# AT91SAM9M10 register map
Vendor: Atmel; File version: 20130207
CPU: 
Registers are 32-bit, read-write, no defined reset value unless marked. A register's access mark holds for its fields unless they carry their own. Offsets are from the block's base; [hi:lo] are bit positions; {n}, {i} and the like mark numbered series.

## VDEC — Video Decoder
Base 0x00900000; register names take the prefix VDEC_
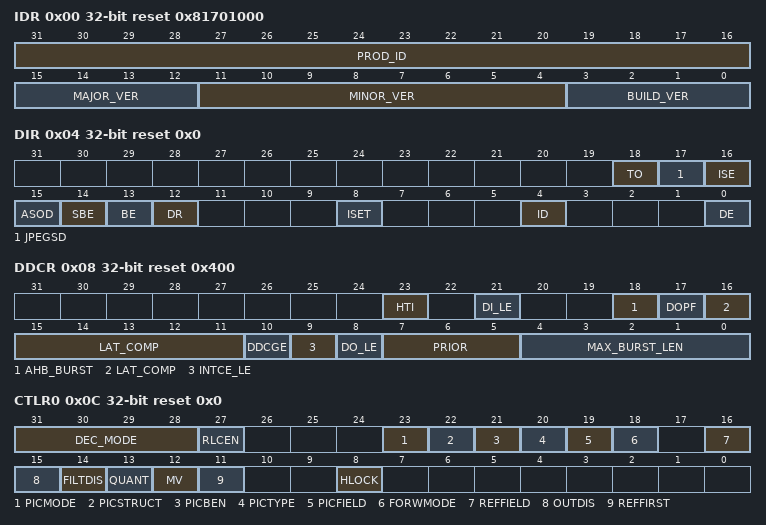
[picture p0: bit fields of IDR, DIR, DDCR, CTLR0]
0x00 IDR ro reset 0x81701000 — ID Register
  [31:16] PROD_ID — Product ID
  [15:12] MAJOR_VER — Major Version
  [11:4] MINOR_VER — Minor Version
  [3:0] BUILD_VER — Build Version
0x04 DIR reset 0x0 — Decoder Interrupt Register
  [18] TO — Timeout
  [17] JPEGSD — JPEG Slice Decoded
  [16] ISE — Input Stream Error
  [15] ASOD — ASO Detected
  [14] SBE — Stream Buffer Empty
  [13] BE — Bus Error
  [12] DR — Decoder Ready
  [8] ISET — Decoder Interrupt Set
  [4] ID — Interrupt Disable
  [0] DE — Decoder Enable
0x08 DDCR reset 0x400 — Decoder Device Configuration Register
  [23] HTI — Hardware Timeout Interrupt Enable
  [21] DI_LE — Decoder Input Endian Mode
  [18] AHB_BURST — AHB Precise Burst and Data Discard Enable
  [17] DOPF — Decoder Output Picture Format
  [16:11] LAT_COMP — Decoder Latency Compensation
  [10] DDCGE — Decoder Dynamic Clock Gating Enable
  [9] INTCE_LE — Interface Endian Mode
  [8] DO_LE — Decoder Output Endian Mode
  [7:5] PRIOR — Decoder Core Internal Bus Service Priority
  [4:0] MAX_BURST_LEN — Maximum Burst Length for Decoder Bus Transactions
0x0C CTLR0 reset 0x0 — Decoder Control Register 0
  [31:28] DEC_MODE — Decoding Mode
  [27] RLCEN — RLC Mode Enable
  [23] PICMODE — Coding mode of Current Picture
  [22] PICSTRUCT — Structure of the Current Picture
  [21] PICBEN — B Picture Enable
  [20] PICTYPE — Picture Type
  [19] PICFIELD — Picture Field
  [18] FORWMODE — Coding Mode of Forward Reference Picture
  [16] REFFIELD — Indicates Which Field Should Be Used As Reference
  [15] OUTDIS — Disable Decoder Output Picture Writing
  [14] FILTDIS — De-block Filtering Disable
  [13] QUANT — Quantization
  [12] MV — MPEG-2 Motion Vector Write Enable
  [11] REFFIRST — Reference Field First
  [8] HLOCK — HLOCK Enable
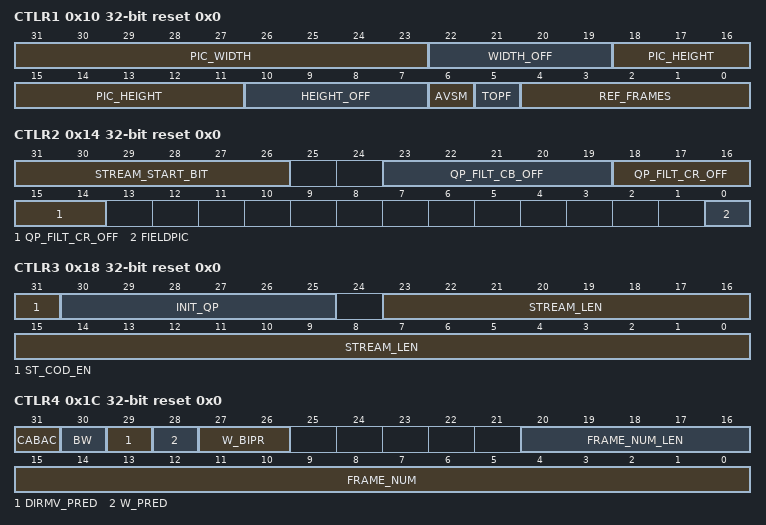
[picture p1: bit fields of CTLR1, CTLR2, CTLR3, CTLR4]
0x10 CTLR1 reset 0x0 — Decoder Control Register 1
  [31:23] PIC_WIDTH — Picture Width
  [22:19] WIDTH_OFF — Width Offset
  [18:11] PIC_HEIGHT — Picture Height
  [10:7] HEIGHT_OFF — Height Offset
  [6] AVSM — Alternative Vertical Scan Method
  [5] TOPF — Top Field
  [4:0] REF_FRAMES — Number of Reference Frames/Semantics
0x14 CTLR2 reset 0x0 — Decoder Control Register 2
  [31:26] STREAM_START_BIT
  [23:19] QP_FILT_CB_OFF
  [18:14] QP_FILT_CR_OFF
  [0] FIELDPIC — Flag for Stream
0x18 CTLR3 reset 0x0 — Decoder Control Register 3
  [31] ST_COD_EN — Stream Start Code
  [30:25] INIT_QP — Quantization Initialization
  [23:0] STREAM_LEN — Stream Length
0x1C CTLR4 reset 0x0 — Decoder Control Register 4
  [31] CABAC — H.264 CABAC Enable
  [30] BW — Black and White Enable
  [29] DIRMV_PRED — Derive Luma Method
  [28] W_PRED — Weight Prediction
  [27:26] W_BIPR — Weight Prediction for B Slices
  [20:16] FRAME_NUM_LEN — Frame Number length
  [15:0] FRAME_NUM — Frame Number
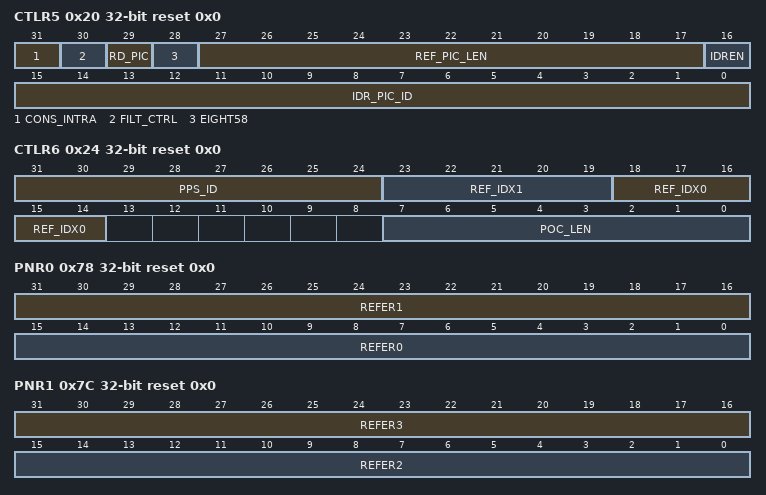
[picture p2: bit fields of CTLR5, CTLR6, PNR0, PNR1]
0x20 CTLR5 reset 0x0 — Decoder Control Register 5
  [31] CONS_INTRA — Intra in Prediction
  [30] FILT_CTRL — Extra Variables Controlling Characteristics of The Deblocking Filter
  [29] RD_PIC — Redundant Picture Present
  [28] EIGHT58
  [27:17] REF_PIC_LEN — Reference Picture Length
  [16] IDREN — IDR Picture Enable
  [15:0] IDR_PIC_ID — IDR Picture
0x24 CTLR6 reset 0x0 — Decoder Control Register 6
  [31:24] PPS_ID — Picture Parameter
  [23:19] REF_IDX1 — Maximum Reference Index 1
  [18:14] REF_IDX0 — Maximum Reference Index 0
  [7:0] POC_LEN — Picture Order length
0x28 DMVBA reset 0x0 — Base Address for Differential Motion Vector
  [31:2] MV_CONTROL_BASE — Differential Motion Vector Base Address
0x2C CTLR7 reset 0x0 — Decoder Control Register 7
  [31:2] BA — Base Address
0x30 RLCVLCBA reset 0x0 — RLC/VLC Data Base Address
  [31:2] BA — Base Address
0x34 PICTBA reset 0x0 — Decoded Picture Base Address
  [31:2] BA — Base Address
{0x38+4i} PIDXBA[{i}] (i=0..15) — Reference Picture Index 0 Base Address
  [31:2] BA — Base Address
0x78 PNR0 reset 0x0 — Reference Picture Numbers Register 0
  [31:16] REFER1 — Reference Picture Number for Index 1
  [15:0] REFER0 — Reference Picture Number for Index 0
0x7C PNR1 reset 0x0 — Reference Picture Numbers Register 1
  [31:16] REFER3 — Reference Picture Number for Index 3
  [15:0] REFER2 — Reference Picture Number for Index 2
0x80 PNR2 reset 0x0 — Reference Picture Numbers Register 2
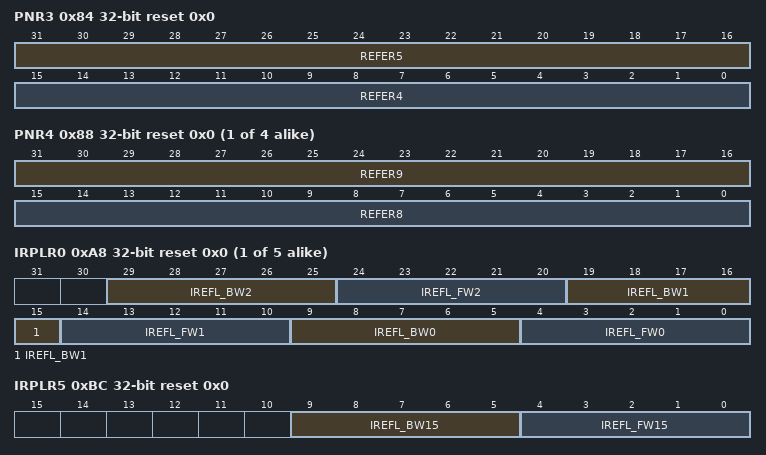
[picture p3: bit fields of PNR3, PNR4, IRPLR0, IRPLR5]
0x84 PNR3 reset 0x0 — Reference Picture Numbers Register 3
  [31:16] REFER5 — Reference Picture Number for Index 5
  [15:0] REFER4 — Reference Picture Number for Index 4
{0x78+4i} PNR{i} reset 0x0 (i=4..7) — Reference Picture Numbers Register {i}
  [31:16] REFER{2i+1} — Reference Picture Number for Index {2i+1}
  [15:0] REFER{2i} — Reference Picture Number for Index {2i}
0x98 PLTFR reset 0x0 — Reference Picture Long Term Flag Register
  [31:0] LTF — Long Term Flag
0x9C PVFR reset 0x0 — Reference Picture Valid Flag Register
0xA0 SDTBA reset 0x0 — Standard Dependent Tables Base Address
  [31:2] BA — Base Address
0xA4 DMMVBA reset 0x0 — Direct Mode Motion Vector Base Address
  [31:2] BA — Base Address
{0xA8+4i} IRPLR{i} reset 0x0 (i=0..4) — H264 Initial Reference Picture List Register {i}
  [29:25] IREFL_BW{3i+2} — Initial Reference Picture List for Backward Picid {3i+2}
  [24:20] IREFL_FW{3i+2} — Initial Reference Picture List for Forward Picid {3i+2}
  [19:15] IREFL_BW{3i+1} — Initial Reference Picture List for Backward Picid {3i+1}
  [14:10] IREFL_FW{3i+1} — Initial Reference Picture List for Forward Picid {3i+1}
  [9:5] IREFL_BW{3i} — Initial Reference Picture List for Backward Picid {3i}
  [4:0] IREFL_FW{3i} — Initial Reference Picture List for Forward Picid {3i}
0xBC IRPLR5 reset 0x0 — H264 Initial Reference Picture List Register 5
  [9:5] IREFL_BW15 — Initial Reference Picture List for Backward Picid 15
  [4:0] IREFL_FW15 — Initial Reference Picture List for Forward Picid 15
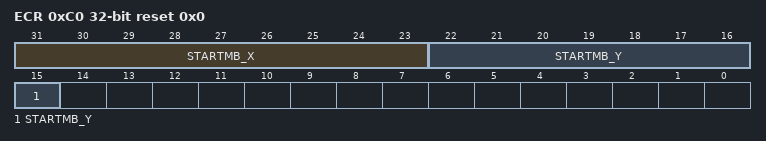
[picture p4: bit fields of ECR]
0xC0 ECR reset 0x0 — Error Concealment Register
  [31:23] STARTMB_X — Start MB from SW for X Dimension
  [22:15] STARTMB_Y — Start MB from SW for Y Dimension
